AUTOSAR XML (schema 4.0)
standard types defined: float32, float64, sint16, sint32, sint8, uint16, uint32, uint8, void, boolean
package /ImplDataTypes
  impl type MultiStateBtn: implementation-data-type=uint8, type-emitter=RTE
  impl type StepMotorStepType: implementation-data-type=uint16, type-emitter=RTE
package /MappingSets
  data type mapping set MappingSet
package /PortInterfaces/ClientServer
  client server interface CsIf_StepMotor
    operation Opr_Move
      arg step: type=StepMotorStepType, direction=IN
package /PortInterfaces/SenderReceiver
  sender receiver interface Srlf_SeatCtrlBtns
    data HeightBtnState: type=MultiStateBtn
    data InclineBtnState: type=MultiStateBtn
    data SlideBtnState: type=MultiStateBtn
  sender receiver interface Srlf_SeatCtrlData
    data Height: type=uint8
    data Incline: type=uint8
    data Slide: type=uint8
package /SoftwareComponents
  application sw component type ECU
    provide port ppSeatCtrlData: provided-interface=Srlf_SeatCtrlData
    behavior Ibhv_ECU: data-type-mapping=MappingSet, handle-termination-and-restart=NO-SUPPORT
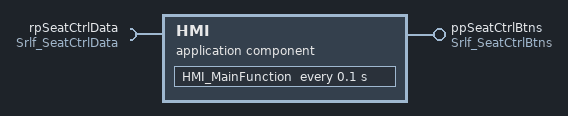
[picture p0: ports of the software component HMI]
  application sw component type HMI
    provide port ppSeatCtrlBtns: provided-interface=Srlf_SeatCtrlBtns
    require port rpSeatCtrlData: required-interface=Srlf_SeatCtrlData
    behavior Ibhv_HMI: data-type-mapping=MappingSet, handle-termination-and-restart=NO-SUPPORT
      timing event TE_HMI_MainFunction_100ms: start-on-event=HMI_MainFunction, period=0.1
      runnable HMI_MainFunction
        data-receive-point-by-arguments:
          access DRP_rpSeatCtrlData_Height: accessed-variable=rpSeatCtrlData.Height
          access DRP_rpSeatCtrlData_Incline: accessed-variable=rpSeatCtrlData.Incline
          access DRP_rpSeatCtrlData_Slide: accessed-variable=rpSeatCtrlData.Slide
        data-send-points:
          access DSP_ppSeatCtrlBtns_HeightBtnState: accessed-variable=ppSeatCtrlBtns.HeightBtnState
          access DSP_ppSeatCtrlBtns_InclineBtnState: accessed-variable=ppSeatCtrlBtns.InclineBtnState
          access DSP_ppSeatCtrlBtns_SlideBtnState: accessed-variable=ppSeatCtrlBtns.SlideBtnState
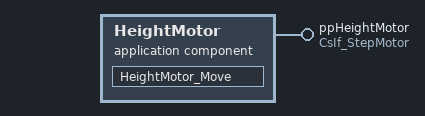
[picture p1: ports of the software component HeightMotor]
  application sw component type HeightMotor
    provide port ppHeightMotor: provided-interface=CsIf_StepMotor
    behavior Ibhv_HeightMotor: data-type-mapping=MappingSet, handle-termination-and-restart=NO-SUPPORT
      operation invoked event OIE_ppHeightMotor_Opr_Move: start-on-event=HeightMotor_Move, operation=ppHeightMotor.Opr_Move
      runnable HeightMotor_Move
  6 x swc implementation, all with programming-language=C, sw-version=1.0.0, vendor-id=255:
    Impl_ECU: behavior=Ibhv_ECU
      code-descriptors:
        code Code: artifact-descriptors=autosar-engineering-object={short-label=SWC.c, category=SWSRC}
      resource consumption ResourceConsumption
    Impl_HMI: behavior=Ibhv_HMI
      code-descriptors:
        code Code: artifact-descriptors=autosar-engineering-object={short-label=SWC.c, category=SWSRC}
      resource consumption ResourceConsumption
    Impl_HeightMotor: behavior=Ibhv_HeightMotor
      code-descriptors:
        code Code: artifact-descriptors=autosar-engineering-object={short-label=SWC.c, category=SWSRC}
      resource consumption ResourceConsumption
    Impl_InclineMotor: behavior=Ibhv_InclineMotor
      code-descriptors:
        code Code: artifact-descriptors=autosar-engineering-object={short-label=SWC.c, category=SWSRC}
      resource consumption ResourceConsumption
    Impl_Seat_Manager: behavior=Ibhv_Seat_Manager
      code-descriptors:
        code Code: artifact-descriptors=autosar-engineering-object={short-label=SWC.c, category=SWSRC}
      resource consumption ResourceConsumption
    Impl_SlideMotor: behavior=Ibhv_SlideMotor
      code-descriptors:
        code Code: artifact-descriptors=autosar-engineering-object={short-label=SWC.c, category=SWSRC}
      resource consumption ResourceConsumption
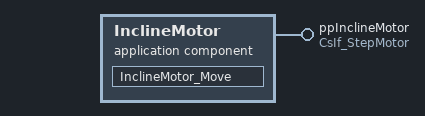
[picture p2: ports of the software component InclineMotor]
  application sw component type InclineMotor
    provide port ppInclineMotor: provided-interface=CsIf_StepMotor
    behavior Ibhv_InclineMotor: data-type-mapping=MappingSet, handle-termination-and-restart=NO-SUPPORT
      operation invoked event OIE_ppInclineMotor_Opr_Move: start-on-event=InclineMotor_Move, operation=ppInclineMotor.Opr_Move
      runnable InclineMotor_Move
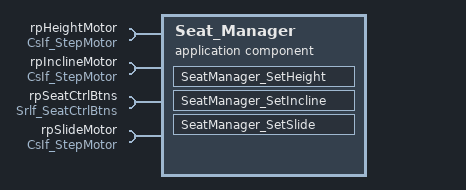
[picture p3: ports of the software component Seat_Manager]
  application sw component type Seat_Manager
    4 x require port:
      rpHeightMotor: required-interface=CsIf_StepMotor
      rpInclineMotor: required-interface=CsIf_StepMotor
      rpSeatCtrlBtns: required-interface=Srlf_SeatCtrlBtns
      rpSlideMotor: required-interface=CsIf_StepMotor
    behavior Ibhv_Seat_Manager: data-type-mapping=MappingSet, handle-termination-and-restart=NO-SUPPORT
      data received event DRE_rpSeatCtrlBtns_HeightBtnState: start-on-event=SeatManager_SetHeight, data=rpSeatCtrlBtns.HeightBtnState
      data received event DRE_rpSeatCtrlBtns_InclineBtnState: start-on-event=SeatManager_SetIncline, data=rpSeatCtrlBtns.InclineBtnState
      data received event DRE_rpSeatCtrlBtns_SlideBtnState: start-on-event=SeatManager_SetSlide, data=rpSeatCtrlBtns.SlideBtnState
      runnable SeatManager_SetHeight
        data-receive-point-by-arguments:
          access DRP_rpSeatCtrlBtns_HeightBtnState: accessed-variable=rpSeatCtrlBtns.HeightBtnState
        sync call SCP_rpHeightMotor_Opr_Move: operation=rpHeightMotor.Opr_Move, timeout=0.0
      runnable SeatManager_SetIncline
        data-receive-point-by-arguments:
          access DRP_rpSeatCtrlBtns_InclineBtnState: accessed-variable=rpSeatCtrlBtns.InclineBtnState
        sync call SCP_rpSlideMotor_Opr_Move: operation=rpSlideMotor.Opr_Move, timeout=0.0
      runnable SeatManager_SetSlide
        data-receive-point-by-arguments:
          access DRP_rpSeatCtrlBtns_SlideBtnState: accessed-variable=rpSeatCtrlBtns.SlideBtnState
        sync call SCP_rpInclineMotor_Opr_Move: operation=rpInclineMotor.Opr_Move, timeout=0.0
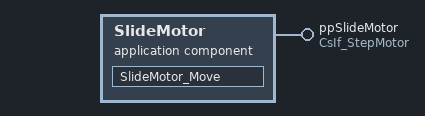
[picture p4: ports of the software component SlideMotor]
  application sw component type SlideMotor
    provide port ppSlideMotor: provided-interface=CsIf_StepMotor
    behavior Ibhv_SlideMotor: data-type-mapping=MappingSet, handle-termination-and-restart=NO-SUPPORT
      operation invoked event OIE_ppSlideMotor_Opr_Move: start-on-event=SlideMotor_Move, operation=ppSlideMotor.Opr_Move
      runnable SlideMotor_Move
package /Compositions
  composition sw component type Task2Composition
    6 x component:
      ECU: type=ECU
      HMI: type=HMI
      HeightMotor: type=HeightMotor
      InclineMotor: type=InclineMotor
      Seat_Manager: type=Seat_Manager
      SlideMotor: type=SlideMotor
    connect ECU.ppSeatCtrlData -> HMI.rpSeatCtrlData
    connect HMI.ppSeatCtrlBtns -> Seat_Manager.rpSeatCtrlBtns
    connect HeightMotor.ppHeightMotor -> Seat_Manager.rpHeightMotor
    connect InclineMotor.ppInclineMotor -> Seat_Manager.rpInclineMotor
    connect SlideMotor.ppSlideMotor -> Seat_Manager.rpSlideMotor
